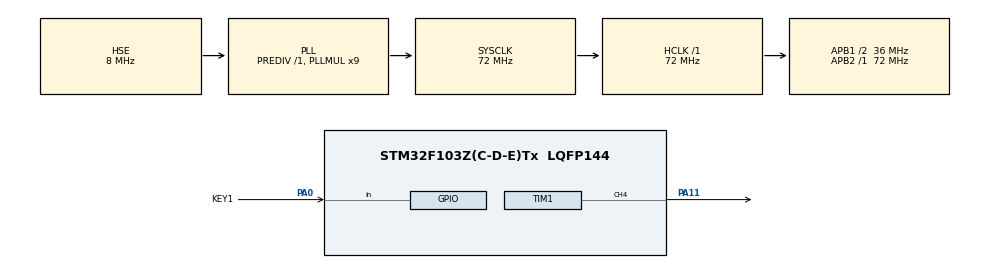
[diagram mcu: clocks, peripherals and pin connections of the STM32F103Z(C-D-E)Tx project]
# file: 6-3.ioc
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Mcu.Family=STM32F1
Mcu.Name=STM32F103Z(C-D-E)Tx
Mcu.Package=LQFP144
NVIC.PriorityGroup=NVIC_PRIORITYGROUP_4
NVIC.TIM1_UP_IRQn=true\:8\:0\:true\:false\:true\:true\:true\:true
NVIC.TIM3_IRQn=true\:9\:0\:true\:false\:true\:true\:true\:true
NVIC.TIM4_IRQn=true\:11\:0\:true\:false\:true\:true\:true\:true
OSC_IN.Mode=HSE-External-Oscillator
OSC_IN.Signal=RCC_OSC_IN
OSC_OUT.Mode=HSE-External-Oscillator
OSC_OUT.Signal=RCC_OSC_OUT
PA0-WKUP.GPIO_Label=KEY1
PA0-WKUP.GPIO_PuPd=GPIO_PULLDOWN
PA0-WKUP.Signal=GPIO_Input
PA11.Signal=S_TIM1_CH4
PA13.Mode=Serial_Wire
PA13.Signal=SYS_JTMS-SWDIO
PA14.Mode=Serial_Wire
PA14.Signal=SYS_JTCK-SWCLK
PC14-OSC32_IN.Mode=LSE-External-Oscillator
PC14-OSC32_IN.Signal=RCC_OSC32_IN
PC15-OSC32_OUT.Mode=LSE-External-Oscillator
PC15-OSC32_OUT.Signal=RCC_OSC32_OUT
ProjectManager.HeapSize=0x200
ProjectManager.StackSize=0x400
ProjectManager.TargetToolchain=MDK-ARM V5.32
RCC.AHBFreq_Value=72000000
RCC.APB1CLKDivider=RCC_HCLK_DIV2
RCC.APB1Freq_Value=36000000
RCC.APB1TimFreq_Value=72000000
RCC.APB2Freq_Value=72000000
RCC.APB2TimFreq_Value=72000000
RCC.HCLKFreq_Value=72000000
RCC.PLLMUL=RCC_PLL_MUL9
RCC.PLLSourceVirtual=RCC_PLLSOURCE_HSE
RCC.SYSCLKFreq_VALUE=72000000
RCC.SYSCLKSource=RCC_SYSCLKSOURCE_PLLCLK
RCC.USBFreq_Value=72000000
SH.S_TIM1_CH4.0=TIM1_CH4,PWM Generation4 CH4
TIM1.AutoReloadPreload=TIM_AUTORELOAD_PRELOAD_ENABLE
TIM1.Channel-PWM\ Generation4\ CH4=TIM_CHANNEL_4
TIM1.Prescaler=5
TIM3.Period=99
TIM3.Prescaler=7199
TIM4.Prescaler=7199
VP_TIM1_VS_ClockSourceINT.Mode=Internal
VP_TIM3_VS_ClockSourceINT.Mode=Internal
VP_TIM4_VS_ClockSourceINT.Mode=Internal
board=custom

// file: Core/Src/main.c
/* USER CODE BEGIN Header */
/**
  ******************************************************************************
  * @file           : main.c
  * @brief          : Main program body
  ******************************************************************************
  * @attention
  *
  * Copyright (c) 2026 STMicroelectronics.
  * All rights reserved.
  *
  * This software is licensed under terms that can be found in the LICENSE file
  * in the root directory of this software component.
  * If no LICENSE file comes with this software, it is provided AS-IS.
  *
  ******************************************************************************
  */
/* USER CODE END Header */
#include "main.h"

/* USER CODE BEGIN Includes */
#include "Beep.h" // 添加蜂鸣器驱动头文件
#include "Key.h"  // 添加按键驱动头文件

/* USER CODE END Includes */

TIM_HandleTypeDef htim1;
TIM_HandleTypeDef htim3;
TIM_HandleTypeDef htim4;

/* USER CODE BEGIN PV */
unsigned char BGM_State = 0; // 背景音乐状态变量

/* USER CODE END PV */

void SystemClock_Config(void);
static void MX_GPIO_Init(void);
static void MX_TIM1_Init(void);
static void MX_TIM3_Init(void);
static void MX_TIM4_Init(void);

int main(void)
{

  /* MCU Configuration--------------------------------------------------------*/

  /* Reset of all peripherals, Initializes the Flash interface and the Systick. */
  HAL_Init();

  /* Configure the system clock */
  SystemClock_Config();

  /* Initialize all configured peripherals */
  MX_GPIO_Init();
  MX_TIM1_Init();
  MX_TIM3_Init();
  MX_TIM4_Init();

  /* USER CODE END 2 */

  /* Infinite loop */
  /* USER CODE BEGIN WHILE */
  while (1)
  {
    Key_Scan(); // 扫描按键状态

    if (Key1Flag)
    {
      Key1Flag = 0; // 清除按键1的标志位
      BGM_State ++; // 下一首背景音乐
      if (BGM_State > 3) // 如果超过乐谱数量，则从头开始
      {
        BGM_State = 1; // 从第一首乐谱开始播放
      }
      char volumeLevel = 5; // 设置音量等级，范围0-10
      switch (BGM_State)
      {
        case 1:
          BGM_Play(volumeLevel, (Note_TypeDef *)TwoTigersNote); // 播放《两只老虎》
          break;
        case 2:
          BGM_Play(volumeLevel, (Note_TypeDef *)PeppaPigNote); // 播放《小猪佩奇》
          break;
        case 3:
          BGM_Play(volumeLevel, (Note_TypeDef *)DouDiZhuNote); // 播放《斗地主》
          break;
        default:
          break;
      }
    }
    /* USER CODE END WHILE */

  }
}

void SystemClock_Config(void)
{
  RCC_OscInitTypeDef RCC_OscInitStruct = {0};
  RCC_ClkInitTypeDef RCC_ClkInitStruct = {0};

  /** Initializes the RCC Oscillators according to the specified parameters
  * in the RCC_OscInitTypeDef structure.
  */
  RCC_OscInitStruct.OscillatorType = RCC_OSCILLATORTYPE_HSE;
  RCC_OscInitStruct.HSEState = RCC_HSE_ON;
  RCC_OscInitStruct.HSEPredivValue = RCC_HSE_PREDIV_DIV1;
  RCC_OscInitStruct.HSIState = RCC_HSI_ON;
  RCC_OscInitStruct.PLL.PLLState = RCC_PLL_ON;
  RCC_OscInitStruct.PLL.PLLSource = RCC_PLLSOURCE_HSE;
  RCC_OscInitStruct.PLL.PLLMUL = RCC_PLL_MUL9;
  if (HAL_RCC_OscConfig(&RCC_OscInitStruct) != HAL_OK)
  {
    Error_Handler();
  }

  /** Initializes the CPU, AHB and APB buses clocks
  */
  RCC_ClkInitStruct.ClockType = RCC_CLOCKTYPE_HCLK|RCC_CLOCKTYPE_SYSCLK
                              |RCC_CLOCKTYPE_PCLK1|RCC_CLOCKTYPE_PCLK2;
  RCC_ClkInitStruct.SYSCLKSource = RCC_SYSCLKSOURCE_PLLCLK;
  RCC_ClkInitStruct.AHBCLKDivider = RCC_SYSCLK_DIV1;
  RCC_ClkInitStruct.APB1CLKDivider = RCC_HCLK_DIV2;
  RCC_ClkInitStruct.APB2CLKDivider = RCC_HCLK_DIV1;

  if (HAL_RCC_ClockConfig(&RCC_ClkInitStruct, FLASH_LATENCY_2) != HAL_OK)
  {
    Error_Handler();
  }
}

static void MX_TIM1_Init(void)
{

  TIM_ClockConfigTypeDef sClockSourceConfig = {0};
  TIM_MasterConfigTypeDef sMasterConfig = {0};
  TIM_OC_InitTypeDef sConfigOC = {0};
  TIM_BreakDeadTimeConfigTypeDef sBreakDeadTimeConfig = {0};

  htim1.Instance = TIM1;
  htim1.Init.Prescaler = 5;
  htim1.Init.CounterMode = TIM_COUNTERMODE_UP;
  htim1.Init.Period = 65535;
  htim1.Init.ClockDivision = TIM_CLOCKDIVISION_DIV1;
  htim1.Init.RepetitionCounter = 0;
  htim1.Init.AutoReloadPreload = TIM_AUTORELOAD_PRELOAD_ENABLE;
  if (HAL_TIM_Base_Init(&htim1) != HAL_OK)
  {
    Error_Handler();
  }
  sClockSourceConfig.ClockSource = TIM_CLOCKSOURCE_INTERNAL;
  if (HAL_TIM_ConfigClockSource(&htim1, &sClockSourceConfig) != HAL_OK)
  {
    Error_Handler();
  }
  if (HAL_TIM_PWM_Init(&htim1) != HAL_OK)
  {
    Error_Handler();
  }
  sMasterConfig.MasterOutputTrigger = TIM_TRGO_RESET;
  sMasterConfig.MasterSlaveMode = TIM_MASTERSLAVEMODE_DISABLE;
  if (HAL_TIMEx_MasterConfigSynchronization(&htim1, &sMasterConfig) != HAL_OK)
  {
    Error_Handler();
  }
  sConfigOC.OCMode = TIM_OCMODE_PWM1;
  sConfigOC.Pulse = 0;
  sConfigOC.OCPolarity = TIM_OCPOLARITY_HIGH;
  sConfigOC.OCFastMode = TIM_OCFAST_DISABLE;
  sConfigOC.OCIdleState = TIM_OCIDLESTATE_RESET;
  sConfigOC.OCNIdleState = TIM_OCNIDLESTATE_RESET;
  if (HAL_TIM_PWM_ConfigChannel(&htim1, &sConfigOC, TIM_CHANNEL_4) != HAL_OK)
  {
    Error_Handler();
  }
  sBreakDeadTimeConfig.OffStateRunMode = TIM_OSSR_DISABLE;
  sBreakDeadTimeConfig.OffStateIDLEMode = TIM_OSSI_DISABLE;
  sBreakDeadTimeConfig.LockLevel = TIM_LOCKLEVEL_OFF;
  sBreakDeadTimeConfig.DeadTime = 0;
  sBreakDeadTimeConfig.BreakState = TIM_BREAK_DISABLE;
  sBreakDeadTimeConfig.BreakPolarity = TIM_BREAKPOLARITY_HIGH;
  sBreakDeadTimeConfig.AutomaticOutput = TIM_AUTOMATICOUTPUT_DISABLE;
  if (HAL_TIMEx_ConfigBreakDeadTime(&htim1, &sBreakDeadTimeConfig) != HAL_OK)
  {
    Error_Handler();
  }
  /* USER CODE BEGIN TIM1_Init 2 */
  HAL_TIM_PWM_Start(&htim1, TIM_CHANNEL_4); // 启动定时器1的PWM功能
  /* USER CODE END TIM1_Init 2 */
  HAL_TIM_MspPostInit(&htim1);

}

static void MX_TIM3_Init(void)
{

  TIM_ClockConfigTypeDef sClockSourceConfig = {0};
  TIM_MasterConfigTypeDef sMasterConfig = {0};

  htim3.Instance = TIM3;
  htim3.Init.Prescaler = 7199;
  htim3.Init.CounterMode = TIM_COUNTERMODE_UP;
  htim3.Init.Period = 99;
  htim3.Init.ClockDivision = TIM_CLOCKDIVISION_DIV1;
  htim3.Init.AutoReloadPreload = TIM_AUTORELOAD_PRELOAD_DISABLE;
  if (HAL_TIM_Base_Init(&htim3) != HAL_OK)
  {
    Error_Handler();
  }
  sClockSourceConfig.ClockSource = TIM_CLOCKSOURCE_INTERNAL;
  if (HAL_TIM_ConfigClockSource(&htim3, &sClockSourceConfig) != HAL_OK)
  {
    Error_Handler();
  }
  sMasterConfig.MasterOutputTrigger = TIM_TRGO_RESET;
  sMasterConfig.MasterSlaveMode = TIM_MASTERSLAVEMODE_DISABLE;
  if (HAL_TIMEx_MasterConfigSynchronization(&htim3, &sMasterConfig) != HAL_OK)
  {
    Error_Handler();
  }
  /* USER CODE BEGIN TIM3_Init 2 */
  __HAL_TIM_CLEAR_FLAG(&htim3, TIM_FLAG_UPDATE); // 清除定时器3的更新标志
  HAL_TIM_Base_Start_IT(&htim3); // 启动定时器3的中断

  /* USER CODE END TIM3_Init 2 */

}

static void MX_TIM4_Init(void)
{

  TIM_ClockConfigTypeDef sClockSourceConfig = {0};
  TIM_MasterConfigTypeDef sMasterConfig = {0};

  htim4.Instance = TIM4;
  htim4.Init.Prescaler = 7199;
  htim4.Init.CounterMode = TIM_COUNTERMODE_UP;
  htim4.Init.Period = 65535;
  htim4.Init.ClockDivision = TIM_CLOCKDIVISION_DIV1;
  htim4.Init.AutoReloadPreload = TIM_AUTORELOAD_PRELOAD_DISABLE;
  if (HAL_TIM_Base_Init(&htim4) != HAL_OK)
  {
    Error_Handler();
  }
  sClockSourceConfig.ClockSource = TIM_CLOCKSOURCE_INTERNAL;
  if (HAL_TIM_ConfigClockSource(&htim4, &sClockSourceConfig) != HAL_OK)
  {
    Error_Handler();
  }
  sMasterConfig.MasterOutputTrigger = TIM_TRGO_RESET;
  sMasterConfig.MasterSlaveMode = TIM_MASTERSLAVEMODE_DISABLE;
  if (HAL_TIMEx_MasterConfigSynchronization(&htim4, &sMasterConfig) != HAL_OK)
  {
    Error_Handler();
  }

}

static void MX_GPIO_Init(void)
{
  GPIO_InitTypeDef GPIO_InitStruct = {0};

  /* GPIO Ports Clock Enable */
  __HAL_RCC_GPIOC_CLK_ENABLE();
  __HAL_RCC_GPIOA_CLK_ENABLE();

  /*Configure GPIO pin : KEY1_Pin */
  GPIO_InitStruct.Pin = KEY1_Pin;
  GPIO_InitStruct.Mode = GPIO_MODE_INPUT;
  GPIO_InitStruct.Pull = GPIO_PULLDOWN;
  HAL_GPIO_Init(KEY1_GPIO_Port, &GPIO_InitStruct);

}

void Error_Handler(void)
{
  __disable_irq();
  while (1)
  {
  }
}
